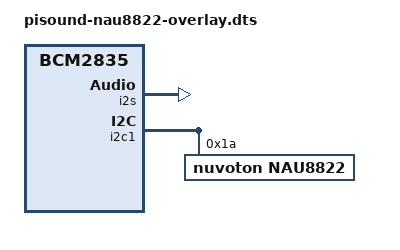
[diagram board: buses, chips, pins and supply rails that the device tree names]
// Definitions for NAU88C22 sound card
/dts-v1/;
/plugin/;

#include <dt-bindings/clock/bcm2835.h>

/ {
	compatible = "brcm,bcm2835";

	fragment@0 {
		target = <&i2s>;
		__overlay__ {
			status = "okay";
		};
	};

	fragment@2 {
		target = <&i2c1>;
		__overlay__ {
			#address-cells = <1>;
			#size-cells = <0>;
			status = "okay";

			nau8822@1a {
				#sound-dai-cells = <0>;
				compatible = "nuvoton,nau8822";
				reg = <0x1a>;
				nuvoton,spk-btl;
				status = "okay";
			};
		};
	};

	fragment@3 {
		target = <&sound>;
		__overlay__ {
			compatible = "nuvoton,pisound-nau8822";
			i2s-controller = <&i2s>;
			nuvoton,clock-rates = <12000000>;
			status = "okay";
		};
	};

};
